# GD32A72_A74x register map
File version: 1.0
CPU: CM7 r2p1, little endian, MPU, FPU, DSP, 4 interrupt priority bits
Registers are 32-bit, read-write, reset 0x0 unless marked. A register's access mark holds for its fields unless they carry their own. Offsets are from the block's base; [hi:lo] are bit positions; {n}, {i} and the like mark numbered series.

## CCTL — Clock control unit
Base 0x49001000
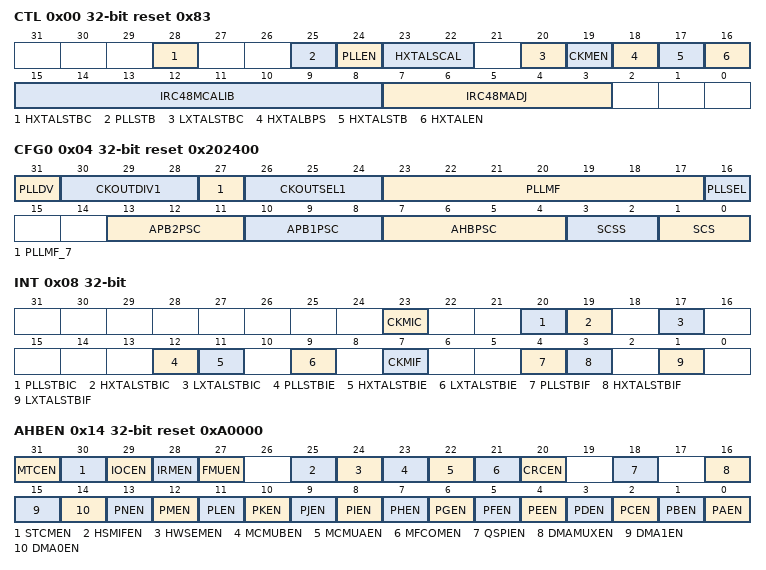
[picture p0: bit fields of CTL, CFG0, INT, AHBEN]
0x00 CTL access per field reset 0x83 — Control register
  [28] HXTALSTBC rw — Clear HXTALSTB
  [25] PLLSTB ro — PLL clock stabilization flag
  [24] PLLEN rw — PLL enable
  [23:22] HXTALSCAL rw — HXTAL frequency scale select
  [20] LXTALSTBC rw — Clear LXTALSTB
  [19] CKMEN rw — HXTAL clock monitor enable
  [18] HXTALBPS rw — External crystal oscillator (HXTAL) clock bypass mode enable
  [17] HXTALSTB rw — External crystal oscillator (HXTAL) clock stabilization flag
  [16] HXTALEN rw — External high speed oscillator enable
  [15:8] IRC48MCALIB rw — Internal 48M RC oscillator calibration value register
  [7:3] IRC48MADJ rw — Internal 48M RC oscillator clock trim adjust value
0x04 CFG0 access per field reset 0x202400 — Configuration register 0
  [31] PLLDV rw — The CK_PLL divide by 1 or 2 for CK_OUT
  [30:28] CKOUTDIV1 rw — The CK_OUT1 divider which the CK_OUT1 frequency can be reduced,
  [27] PLLMF_7 rw — Bit 7 of PLLMF register
  [26:24] CKOUTSEL1 rw — CK_OUT1 clock source selection
  [23:17] PLLMF rw — PLL multiply factors
  [16] PLLSEL rw — PLL clock source selection
  [13:11] APB2PSC rw — APB2 prescaler selection
  [10:8] APB1PSC rw — APB1 prescaler selection
  [7:4] AHBPSC rw — AHB prescaler selection
  [3:2] SCSS ro — System clock switch status
  [1:0] SCS rw — System clock switch
0x08 INT access per field — Interrupt register
  [23] CKMIC wo — HXTAL clock stuck interrupt clear
  [20] PLLSTBIC wo — PLL stabilization interrupt clear
  [19] HXTALSTBIC wo — HXTAL stabilization interrupt clear
  [17] LXTALSTBIC wo — LXTAL stabilization interrupt clear
  [12] PLLSTBIE rw — PLL stabilization interrupt enable
  [11] HXTALSTBIE rw — HXTAL stabilization interrupt enable
  [9] LXTALSTBIE rw — LXTAL stabilization interrupt enable
  [7] CKMIF ro — HXTAL clock stuck interrupt flag
  [4] PLLSTBIF ro — PLL stabilization interrupt flag
  [3] HXTALSTBIF ro — HXTAL stabilization interrupt flag
  [1] LXTALSTBIF ro — LXTAL stabilization interrupt flag
0x14 AHBEN reset 0xA0000 — AHB enable register
  [31] MTCEN — MTC clock enable
  [30] STCMEN — STCM clock enable
  [29] IOCEN — IOC clock enable
  [28] IRMEN — IRM clock enable
  [27] FMUEN — FMU clock enable
  [25] HSMIFEN — HSMIF clock enable
  [24] HWSEMEN — HWSEM clock enable
  [23] MCMUBEN — MCMUB clock enable
  [22] MCMUAEN — MCMUA clock enable
  [21] MFCOMEN — MFCOM port A clock enable
  [20] CRCEN — CRC clock enable
  [18] QSPIEN — QSPI clock enable
  [16] DMAMUXEN — DMAMUX clock enable
  [15] DMA1EN — DMA1 clock enable
  [14] DMA0EN — DMA0 clock enable
  [13] PNEN — GPIO port N clock enable
  [12] PMEN — GPIO port M clock enable
  [11] PLEN — GPIO port L clock enable
  [10] PKEN — GPIO port K clock enable
  [9] PJEN — GPIO port J clock enable
  [8] PIEN — GPIO port I clock enable
  [7] PHEN — GPIO port H clock enable
  [6] PGEN — GPIO port G clock enable
  [5] PFEN — GPIO port F clock enable
  [4] PEEN — GPIO port E clock enable
  [3] PDEN — GPIO port D clock enable
  [2] PCEN — GPIO port C clock enable
  [1] PBEN — GPIO port B clock enable
  [0] PAEN — GPIO port A clock enable
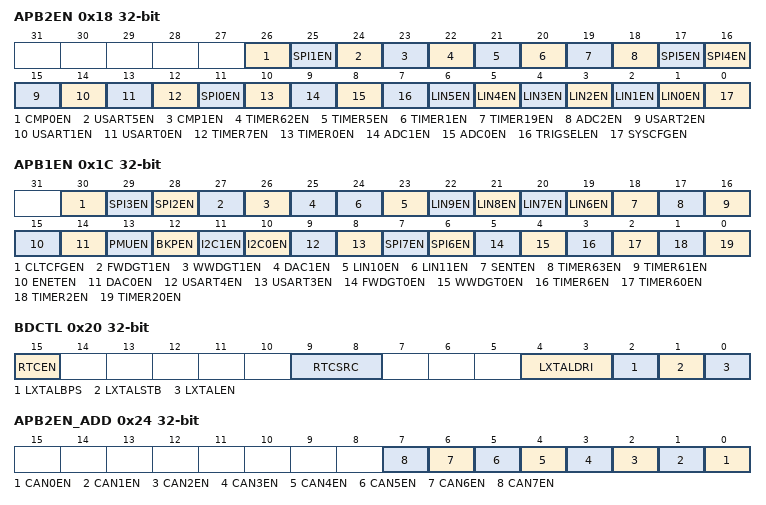
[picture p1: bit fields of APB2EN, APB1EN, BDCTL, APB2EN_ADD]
0x18 APB2EN — APB2 reset register
  [26] CMP0EN — Comparator0 clock enable
  [25] SPI1EN — SPI1 clock enable
  [24] USART5EN — USART5 clock enable
  [23] CMP1EN — Comparator1 clock enable
  [22] TIMER62EN — TIMER62 timer clock enable
  [21] TIMER5EN — TIMER5 timer clock enable
  [20] TIMER1EN — TIMER1 timer clock enable
  [19] TIMER19EN — TIMER19 timer clock enable
  [18] ADC2EN — ADC2 interface clock enable
  [17] SPI5EN — SPI5 clock enable
  [16] SPI4EN — SPI4 clock enable
  [15] USART2EN — USART2 clock enable
  [14] USART1EN — USART1 clock enable
  [13] USART0EN — USART0 clock enable
  [12] TIMER7EN — TIMER7 timer clock enable
  [11] SPI0EN — SPI0 clock enable
  [10] TIMER0EN — TIMER0 timer clock enable
  [9] ADC1EN — ADC1 interface clock enable
  [8] ADC0EN — ADC interface clock enable
  [7] TRIGSELEN — TRIGSEL clock enable
  [n+1] LIN{n}EN (n=0..5) — LIN{n} clock enable
  [0] SYSCFGEN — System configuration clock enable
0x1C APB1EN — APB1 enable register
  [30] CLTCFGEN — CLTCFG clock enable
  [29] SPI3EN — SPI3 clock enable
  [28] SPI2EN — SPI2 clock enable
  [27] FWDGT1EN — Free watchdog timer clock enable
  [26] WWDGT1EN — Window watchdog timer clock enable
  [25] DAC1EN — DAC1clock enable
  [n+13] LIN{n}EN (n=6..11) — LIN{n} clock enable
  [18] SENTEN — SENT timer clock enable
  [17] TIMER63EN — TIMER63 timer clock enable
  [16] TIMER61EN — TIMER61 timer clock enable
  [15] ENETEN — ENET clock enable
  [14] DAC0EN — DAC0 clock enable
  [13] PMUEN — Power interface clock enable
  [12] BKPEN — Back-up interface clock enable
  [11] I2C1EN — I2C1 clock enable
  [10] I2C0EN — I2C0 clock enable
  [9] USART4EN — USART4 clock enable
  [8] USART3EN — USART3 clock enable
  [7] SPI7EN — SPI7 clock enable
  [6] SPI6EN — SPI6 clock enable
  [5] FWDGT0EN — Free watchdog timer clock enable
  [4] WWDGT0EN — Window watchdog timer clock enable
  [3] TIMER6EN — TIMER6 timer clock enable
  [2] TIMER60EN — TIMER60 timer clock enable
  [1] TIMER2EN — TIMER2 timer clock enable
  [0] TIMER20EN — TIMER20 timer clock enable
0x20 BDCTL access per field — Backup domain control register
  [15] RTCEN rw — RTC clock enable
  [9:8] RTCSRC rw — RTC clock entry selection
  [4:3] LXTALDRI rw — LXTAL drive capability
  [2] LXTALBPS rw — LXTAL bypass mode enable
  [1] LXTALSTB ro — External low-speed oscillator stabilization
  [0] LXTALEN rw — LXTAL enable
0x24 APB2EN_ADD — APB2 enable additional register
  [n] CAN{n}EN (n=0..7) — CAN{n} clock enable
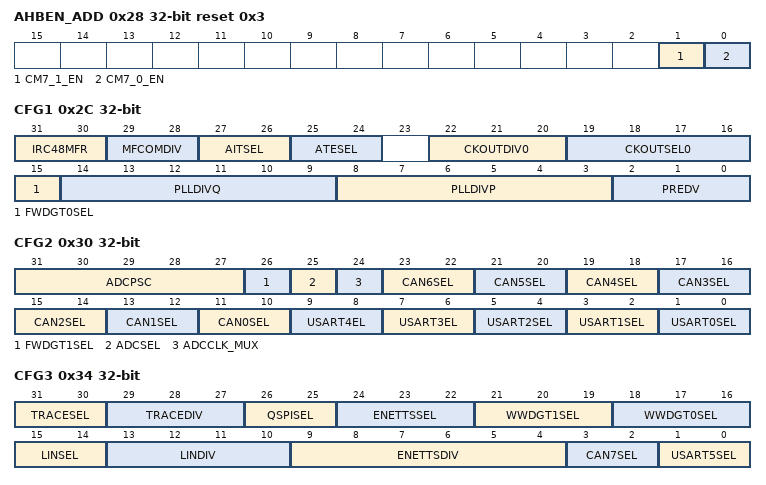
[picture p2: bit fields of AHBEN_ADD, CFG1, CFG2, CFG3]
0x28 AHBEN_ADD reset 0x3 — AHB enable additional register
  [1] CM7_1_EN — CPU CM7_1 clock enable
  [0] CM7_0_EN — CPU CM7_0 clock enable
0x2C CFG1 — Configuration register 1
  [31:30] IRC48MFR — RC48M fail response
  [29:28] MFCOMDIV — MFCOM divider which the MFCOM HCLK frequency can be reduced
  [27:26] AITSEL — AIT clock of STCM
  [25:24] ATESEL — ATE clock of STCM
  [22:20] CKOUTDIV0 — The CK_OUT0 divider which the CK_OUT0 frequency can be reduced,
  [19:16] CKOUTSEL0 — CK_OUT0 clock source selection
  [15] FWDGT0SEL — FWDGT0 clock select
  [14:9] PLLDIVQ — PLLQ VCO clock divider
  [8:3] PLLDIVP — PLLP VCO clock divider
  [2:0] PREDV — CK_HXTAL divider previous PLL
0x30 CFG2 — Configuration register 2
  [31:27] ADCPSC — ADC clock prescaler selection, Set and cleared by software
  [26] FWDGT1SEL — FWDGT1 clock select
  [25] ADCSEL — ADC clock source selection
  [24] ADCCLK_MUX — ADCCLK mux signal
  [2n+11:2n+10] CAN{n}SEL (n=0..6) — CK_CAN{n} clock source selection
  [9:8] USART4EL — CK_USART4 clock source selection
  [7:6] USART3EL — CK_USART3 clock source selection
  [5:4] USART2SEL — CK_USART2 clock source selection
  [3:2] USART1SEL — CK_USART1 clock source selection
  [1:0] USART0SEL — CK_USART0 clock source selection
0x34 CFG3 — Configuration register 3
  [31:30] TRACESEL — TRACE clock source selection
  [29:27] TRACEDIV — TRACE clock divider
  [26:25] QSPISEL — QSPI clock source selection
  [24:22] ENETTSSEL — ENETTS clock source selection
  [21:19] WWDGT1SEL — WWDGT1 clock select
  [18:16] WWDGT0SEL — WWDGT0 clock select
  [15:14] LINSEL — LIN clock select
  [13:10] LINDIV — CK_LIN divider
  [9:4] ENETTSDIV — ENETTS TS CLK divider
  [3:2] CAN7SEL — CK_CAN7clock source selection
  [1:0] USART5SEL — CK_USART5 clock source selection
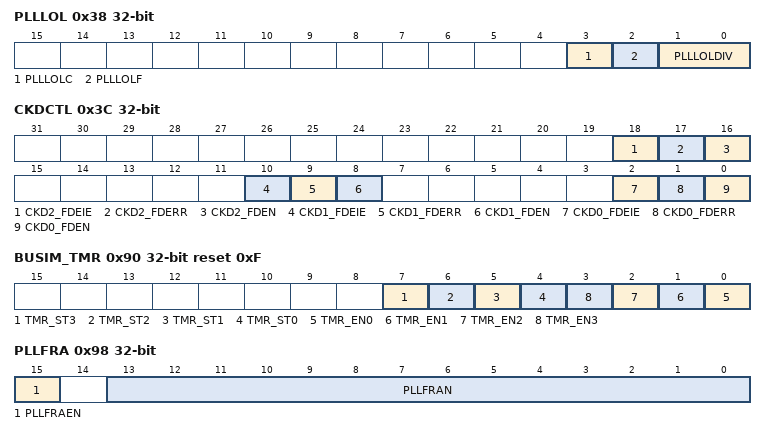
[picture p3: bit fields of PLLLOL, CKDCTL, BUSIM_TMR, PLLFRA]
0x38 PLLLOL access per field — PLL loss of lock register
  [3] PLLLOLC rw — Clear PLLLOLC
  [2] PLLLOLF ro — Loss of lock detector flag
  [1:0] PLLLOLDIV rw — Adjust the loss of lock accuracy
0x3C CKDCTL — Clock detect control register
  [18] CKD2_FDEIE — Frequency detect error interrupt enable
  [17] CKD2_FDERR — Frequency detect error
  [16] CKD2_FDEN — Frequency detect Enable
  [10] CKD1_FDEIE — Frequency detect error interrupt enable
  [9] CKD1_FDERR — Frequency detect error
  [8] CKD1_FDEN — Frequency detect enable
  [2] CKD0_FDEIE — Frequency detect error interrupt enable
  [1] CKD0_FDERR — Frequency detect error
  [0] CKD0_FDEN — Frequency detect enable
0x90 BUSIM_TMR reset 0xF — TMR register
  [7] TMR_ST3 — TRIM register TMR error status
  [6] TMR_ST2 — CLK monitor enable register TMR error status
  [5] TMR_ST1 — CLK enable TMR error status
  [4] TMR_ST0 — SW software register TMR error status
  [n] TMR_EN{n} (n=0..3) — TMR error {n} output to fmu enable
0x98 PLLFRA — PLL fraction configuration register
  [15] PLLFRAEN — PLL fractional latch enable
  [13:0] PLLFRAN — Fractional part of the multiplication factor for PLL VCO
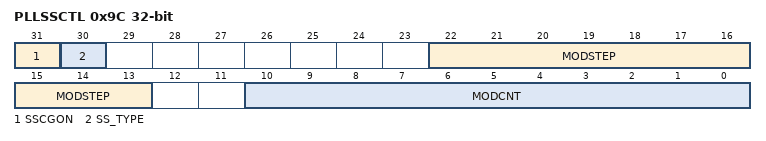
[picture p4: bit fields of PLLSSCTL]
0x9C PLLSSCTL — PLL clock spread spectrum control register
  [31] SSCGON — PLL spread spectrum modulation is enabled
  [30] SS_TYPE — PLL spread spectrum modulation type selection
  [22:13] MODSTEP — These bits are configured with PLL spread spectrum modulation curve amplitude
  [10:0] MODCNT — These bits are configured with PLL spread spectrum modulation curve frequency
